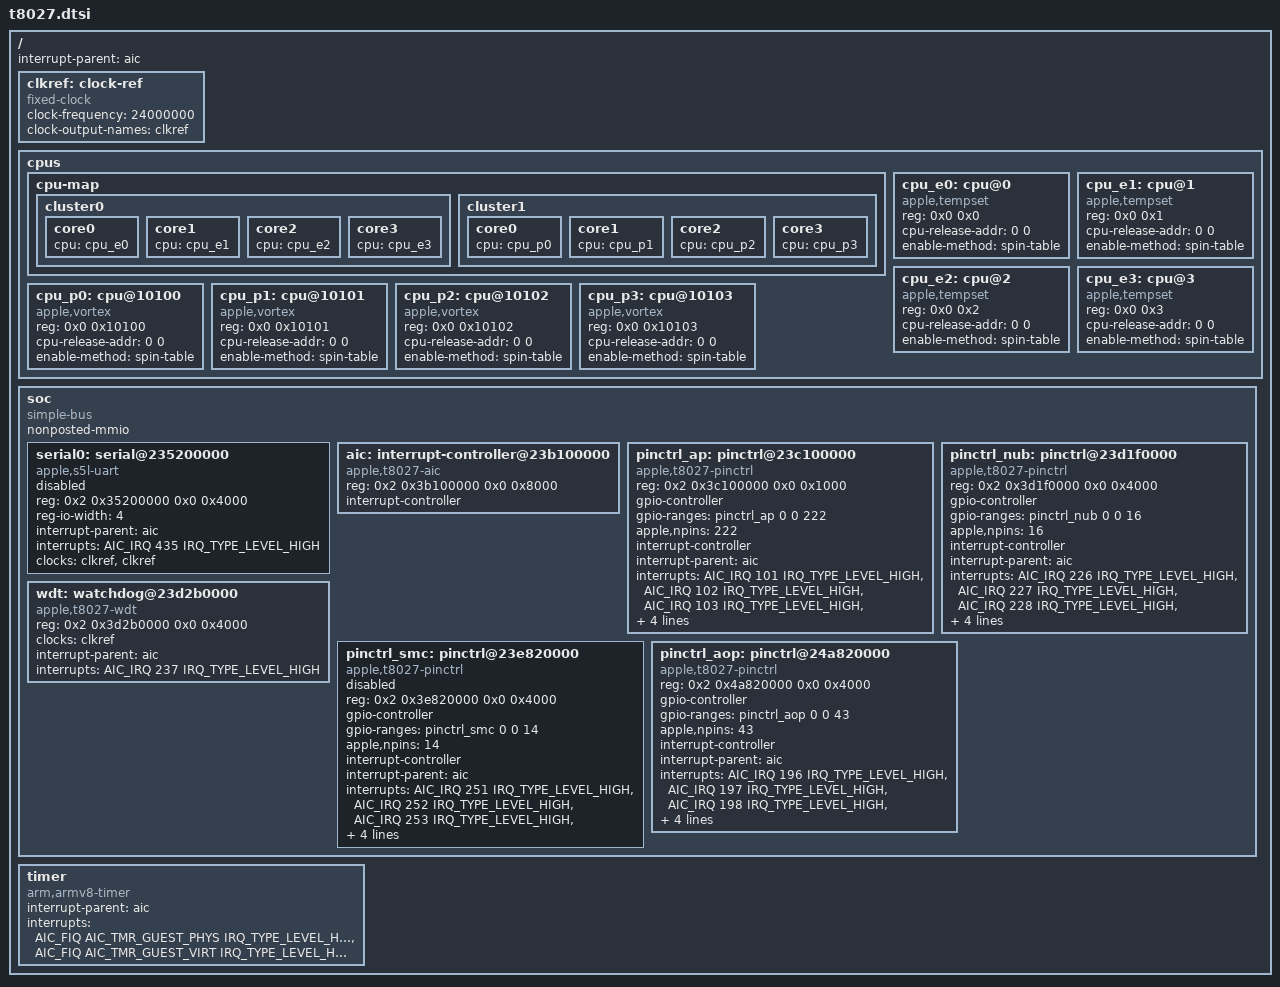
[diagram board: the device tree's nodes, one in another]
// SPDX-License-Identifier: GPL-2.0+ OR MIT
/*
 * Apple T8027 "A12X/Z" SoC
 *
 * Other names: H11G, "Aruba"
 *
 * Copyright (c) 2024, Nick Chan <towinchenmi@gmail.com>
 */

#include <dt-bindings/gpio/gpio.h>
#include <dt-bindings/interrupt-controller/apple-aic.h>
#include <dt-bindings/interrupt-controller/irq.h>
#include <dt-bindings/pinctrl/apple.h>

/ {
	interrupt-parent = <&aic>;
	#address-cells = <2>;
	#size-cells = <2>;

	clkref: clock-ref {
		compatible = "fixed-clock";
		#clock-cells = <0>;
		clock-frequency = <24000000>;
		clock-output-names = "clkref";
	};

	cpus {
		#address-cells = <2>;
		#size-cells = <0>;

		cpu-map {
			cluster0 {
				core0 {
					cpu = <&cpu_e0>;
				};
				core1 {
					cpu = <&cpu_e1>;
				};
				core2 {
					cpu = <&cpu_e2>;
				};
				core3 {
					cpu = <&cpu_e3>;
				};
			};

			cluster1 {
				core0 {
					cpu = <&cpu_p0>;
				};
				core1 {
					cpu = <&cpu_p1>;
				};
				core2 {
					cpu = <&cpu_p2>;
				};
				core3 {
					cpu = <&cpu_p3>;
				};
			};
		};

		cpu_e0: cpu@0 {
			compatible = "apple,tempset";
			reg = <0x0 0x0>;
			cpu-release-addr = <0 0>; /* To be filled by loader */
			enable-method = "spin-table";
			device_type = "cpu";
		};

		cpu_e1: cpu@1 {
			compatible = "apple,tempset";
			reg = <0x0 0x1>;
			cpu-release-addr = <0 0>; /* To be filled by loader */
			enable-method = "spin-table";
			device_type = "cpu";
		};

		cpu_e2: cpu@2 {
			compatible = "apple,tempset";
			reg = <0x0 0x2>;
			cpu-release-addr = <0 0>; /* To be filled by loader */
			enable-method = "spin-table";
			device_type = "cpu";
		};

		cpu_e3: cpu@3 {
			compatible = "apple,tempset";
			reg = <0x0 0x3>;
			cpu-release-addr = <0 0>; /* To be filled by loader */
			enable-method = "spin-table";
			device_type = "cpu";
		};

		cpu_p0: cpu@10100 {
			compatible = "apple,vortex";
			reg = <0x0 0x10100>;
			cpu-release-addr = <0 0>; /* To be filled by loader */
			enable-method = "spin-table";
			device_type = "cpu";
		};

		cpu_p1: cpu@10101 {
			compatible = "apple,vortex";
			reg = <0x0 0x10101>;
			cpu-release-addr = <0 0>; /* To be filled by loader */
			enable-method = "spin-table";
			device_type = "cpu";
		};

		cpu_p2: cpu@10102 {
			compatible = "apple,vortex";
			reg = <0x0 0x10102>;
			cpu-release-addr = <0 0>; /* To be filled by loader */
			enable-method = "spin-table";
			device_type = "cpu";
		};

		cpu_p3: cpu@10103 {
			compatible = "apple,vortex";
			reg = <0x0 0x10103>;
			cpu-release-addr = <0 0>; /* To be filled by loader */
			enable-method = "spin-table";
			device_type = "cpu";
		};
	};

	soc {
		compatible = "simple-bus";
		#address-cells = <2>;
		#size-cells = <2>;
		nonposted-mmio;
		ranges;

		serial0: serial@235200000 {
			compatible = "apple,s5l-uart";
			reg = <0x2 0x35200000 0x0 0x4000>;
			reg-io-width = <4>;
			interrupt-parent = <&aic>;
			interrupts = <AIC_IRQ 435 IRQ_TYPE_LEVEL_HIGH>;
			/* Use the bootloader-enabled clocks for now. */
			clocks = <&clkref>, <&clkref>;
			clock-names = "uart", "clk_uart_baud0";
			status = "disabled";
		};

		aic: interrupt-controller@23b100000 {
			compatible = "apple,t8027-aic", "apple,t8103-aic", "apple,aic";
			reg = <0x2 0x3b100000 0x0 0x8000>;
			#interrupt-cells = <3>;
			interrupt-controller;
		};

		pinctrl_ap: pinctrl@23c100000 {
			compatible = "apple,t8027-pinctrl", "apple,pinctrl";
			reg = <0x2 0x3c100000 0x0 0x1000>;

			gpio-controller;
			#gpio-cells = <2>;
			gpio-ranges = <&pinctrl_ap 0 0 222>;
			apple,npins = <222>;

			interrupt-controller;
			#interrupt-cells = <2>;
			interrupt-parent = <&aic>;
			interrupts = <AIC_IRQ 101 IRQ_TYPE_LEVEL_HIGH>,
				     <AIC_IRQ 102 IRQ_TYPE_LEVEL_HIGH>,
				     <AIC_IRQ 103 IRQ_TYPE_LEVEL_HIGH>,
				     <AIC_IRQ 104 IRQ_TYPE_LEVEL_HIGH>,
				     <AIC_IRQ 105 IRQ_TYPE_LEVEL_HIGH>,
				     <AIC_IRQ 106 IRQ_TYPE_LEVEL_HIGH>,
				     <AIC_IRQ 107 IRQ_TYPE_LEVEL_HIGH>;
		};

		pinctrl_nub: pinctrl@23d1f0000 {
			compatible = "apple,t8027-pinctrl", "apple,pinctrl";
			reg = <0x2 0x3d1f0000 0x0 0x4000>;

			gpio-controller;
			#gpio-cells = <2>;
			gpio-ranges = <&pinctrl_nub 0 0 16>;
			apple,npins = <16>;

			interrupt-controller;
			#interrupt-cells = <2>;
			interrupt-parent = <&aic>;
			interrupts = <AIC_IRQ 226 IRQ_TYPE_LEVEL_HIGH>,
				     <AIC_IRQ 227 IRQ_TYPE_LEVEL_HIGH>,
				     <AIC_IRQ 228 IRQ_TYPE_LEVEL_HIGH>,
				     <AIC_IRQ 229 IRQ_TYPE_LEVEL_HIGH>,
				     <AIC_IRQ 233 IRQ_TYPE_LEVEL_HIGH>,
				     <AIC_IRQ 234 IRQ_TYPE_LEVEL_HIGH>,
				     <AIC_IRQ 235 IRQ_TYPE_LEVEL_HIGH>;
		};

		wdt: watchdog@23d2b0000 {
			compatible = "apple,t8027-wdt", "apple,wdt";
			reg = <0x2 0x3d2b0000 0x0 0x4000>;
			clocks = <&clkref>;
			interrupt-parent = <&aic>;
			interrupts = <AIC_IRQ 237 IRQ_TYPE_LEVEL_HIGH>;
		};

		pinctrl_smc: pinctrl@23e820000 {
			compatible = "apple,t8027-pinctrl", "apple,pinctrl";
			reg = <0x2 0x3e820000 0x0 0x4000>;

			gpio-controller;
			#gpio-cells = <2>;
			gpio-ranges = <&pinctrl_smc 0 0 14>;
			apple,npins = <14>;

			interrupt-controller;
			#interrupt-cells = <2>;
			interrupt-parent = <&aic>;
			interrupts = <AIC_IRQ 251 IRQ_TYPE_LEVEL_HIGH>,
				     <AIC_IRQ 252 IRQ_TYPE_LEVEL_HIGH>,
				     <AIC_IRQ 253 IRQ_TYPE_LEVEL_HIGH>,
				     <AIC_IRQ 254 IRQ_TYPE_LEVEL_HIGH>,
				     <AIC_IRQ 255 IRQ_TYPE_LEVEL_HIGH>,
				     <AIC_IRQ 256 IRQ_TYPE_LEVEL_HIGH>,
				     <AIC_IRQ 257 IRQ_TYPE_LEVEL_HIGH>;
			/*
			 * SMC is not yet supported and accessing this pinctrl while SMC is
			 * suspended results in a hang.
			 */
			status = "disabled";
		};

		pinctrl_aop: pinctrl@24a820000 {
			compatible = "apple,t8027-pinctrl", "apple,pinctrl";
			reg = <0x2 0x4a820000 0x0 0x4000>;

			gpio-controller;
			#gpio-cells = <2>;
			gpio-ranges = <&pinctrl_aop 0 0 43>;
			apple,npins = <43>;

			interrupt-controller;
			#interrupt-cells = <2>;
			interrupt-parent = <&aic>;
			interrupts = <AIC_IRQ 196 IRQ_TYPE_LEVEL_HIGH>,
				     <AIC_IRQ 197 IRQ_TYPE_LEVEL_HIGH>,
				     <AIC_IRQ 198 IRQ_TYPE_LEVEL_HIGH>,
				     <AIC_IRQ 199 IRQ_TYPE_LEVEL_HIGH>,
				     <AIC_IRQ 200 IRQ_TYPE_LEVEL_HIGH>,
				     <AIC_IRQ 201 IRQ_TYPE_LEVEL_HIGH>,
				     <AIC_IRQ 202 IRQ_TYPE_LEVEL_HIGH>;
		};
	};

	timer {
		compatible = "arm,armv8-timer";
		interrupt-parent = <&aic>;
		interrupt-names = "phys", "virt";
		/* Note that A12X/Z doesn't actually have a hypervisor (EL2 is not implemented). */
		interrupts = <AIC_FIQ AIC_TMR_GUEST_PHYS IRQ_TYPE_LEVEL_HIGH>,
			     <AIC_FIQ AIC_TMR_GUEST_VIRT IRQ_TYPE_LEVEL_HIGH>;
	};
};
